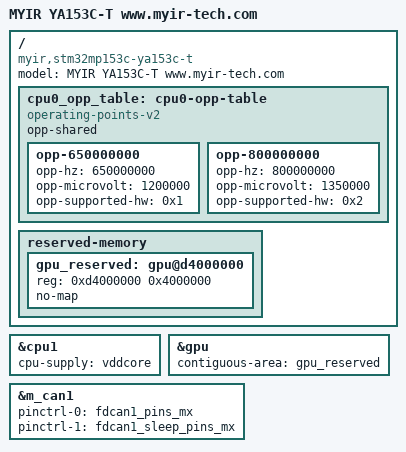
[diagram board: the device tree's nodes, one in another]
// SPDX-License-Identifier: (GPL-2.0+ OR BSD-3-Clause)
/*
 * Based on stm32mp157a device number configuration
 * Author: licy.li@myirtech.com
 */

/dts-v1/;

//#include "stm32mp153c.dtsi"
#include "stm32mp151c-ya151c-t.dts"
//#include "stm32mp153cac-ya153c-pinctrl.dtsi"
#include <dt-bindings/rtc/rtc-stm32.h>


/ {
	model = "MYIR YA153C-T www.myir-tech.com";
	compatible = "myir,stm32mp153c-ya153c-t", "st,stm32mp157c-dk2", "st,stm32mp157";

	cpu0_opp_table: cpu0-opp-table {
          	compatible = "operating-points-v2";
          	opp-shared;
          	opp-650000000 {
                     	 opp-hz = /bits/ 64 <650000000>;                                                                                                                                                    
                     	opp-microvolt = <1200000>;
                     	 opp-supported-hw = <0x1>;
                 };
		 opp-800000000 {
			opp-hz = /bits/ 64 <800000000>;
			opp-microvolt = <1350000>;
			opp-supported-hw = <0x2>;
		};

     	};

	reserved-memory {
		gpu_reserved: gpu@d4000000 {
			reg = <0xd4000000 0x4000000>;
			no-map;
		};

	};

};

&cpu1{
	cpu-supply = <&vddcore>;
};


&gpu {
	contiguous-area = <&gpu_reserved>;
	status = "okay";
};


/*fd_can*/
&m_can1{
	pinctrl-names = "default", "sleep";
	pinctrl-0 = <&fdcan1_pins_mx>;
	pinctrl-1 = <&fdcan1_sleep_pins_mx>;
	status = "okay";
};

